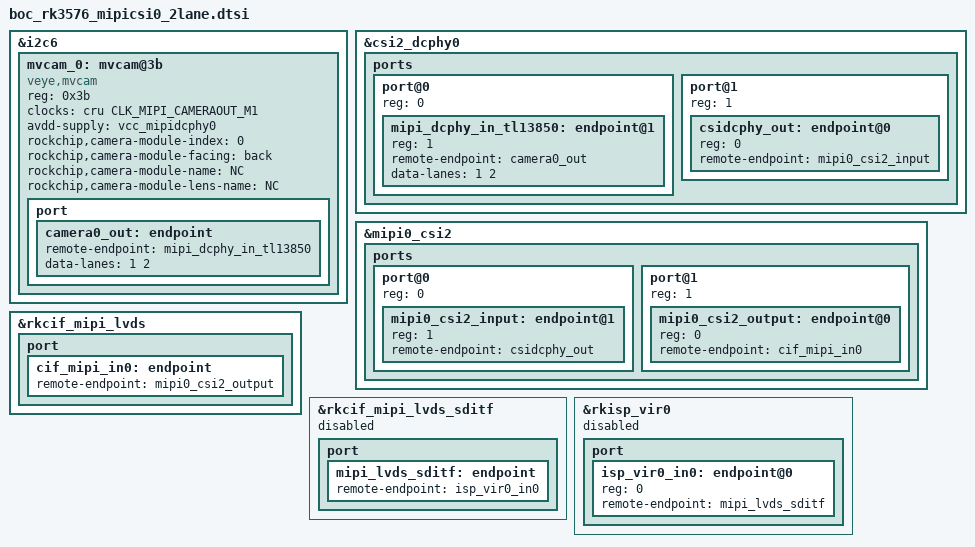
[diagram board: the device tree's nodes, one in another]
&i2c6 {
        mvcam_0: mvcam@3b{
               compatible = "veye,mvcam";
               reg = <0x3b>;
               clocks = <&cru CLK_MIPI_CAMERAOUT_M1>;
        //        clocks = <&veye_mv265_clk>;
               clock-names = "xvclk";
               pinctrl-names = "default";
	//        pinctrl-0 = <&mipi_csi0_reset>;
	//        reset-gpios = <&gpio3 RK_PC6 GPIO_ACTIVE_HIGH>;
        //        pwdn-gpios = <&xl9555 8 GPIO_ACTIVE_HIGH>;
        //        power-domains = <&power RK3576_PD_VI>;

               avdd-supply = <&vcc_mipidcphy0>;
               rockchip,camera-module-index = <0>;
               rockchip,camera-module-facing = "back";
               rockchip,camera-module-name = "NC";
               rockchip,camera-module-lens-name = "NC";
               port {
                        camera0_out: endpoint {
                                remote-endpoint = <&mipi_dcphy_in_tl13850>;
                                data-lanes = <1 2>;
                       };
               };
       };
};

&csi2_dcphy0 {
	status = "okay";

	ports {
            #address-cells = <1>;
            #size-cells = <0>;
            port@0 {
                    reg = <0>;
		    #address-cells = <1>;
                    #size-cells = <0>;

                    mipi_dcphy_in_tl13850: endpoint@1 {
                            reg = <1>;
                            remote-endpoint = <&camera0_out>;
                            data-lanes = <1 2>;
                    };
            };
            port@1 {
                    reg = <1>;
                    #address-cells = <1>;
                    #size-cells = <0>;

                    csidcphy_out: endpoint@0 {
                        reg = <0>;
                            remote-endpoint = <&mipi0_csi2_input>;
                    };
            };
        };
};


&mipi0_csi2 {
        status = "okay";

        ports {
                #address-cells = <1>;
                #size-cells = <0>;

                port@0 {
                        reg = <0>;
                        #address-cells = <1>;
                        #size-cells = <0>;

                        mipi0_csi2_input: endpoint@1 {
                                reg = <1>;
                                remote-endpoint = <&csidcphy_out>;
                        };
                };

                port@1 {
                        reg = <1>;
                        #address-cells = <1>;
                        #size-cells = <0>;

                        mipi0_csi2_output: endpoint@0 {
                                reg = <0>;
                                remote-endpoint = <&cif_mipi_in0>;
                        };
                };
        };
};


&rkcif_mipi_lvds {
        status = "okay";

        port {
                cif_mipi_in0: endpoint {
                        remote-endpoint = <&mipi0_csi2_output>;
                };
        };
};


&rkcif_mipi_lvds_sditf {
	status = "disabled";

	port {
                mipi_lvds_sditf: endpoint {
                        remote-endpoint = <&isp_vir0_in0>;
                };
        };
};


&rkisp_vir0 {
        status = "disabled";

        port {
                #address-cells = <1>;
                #size-cells = <0>;

                isp_vir0_in0: endpoint@0 {
                        reg = <0>;
                        remote-endpoint = <&mipi_lvds_sditf>;
                };
        };
};
